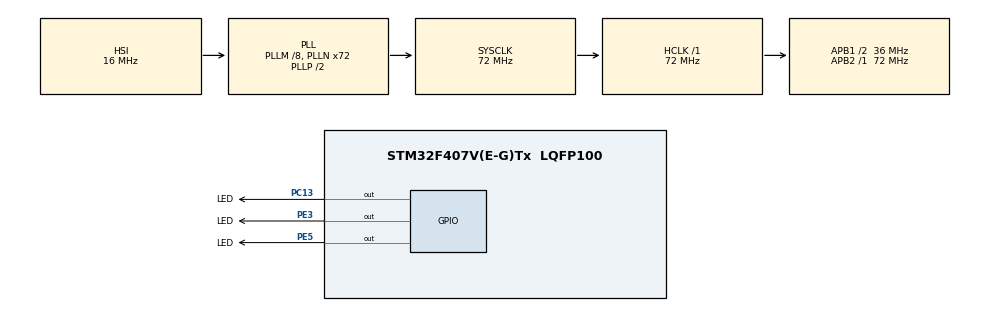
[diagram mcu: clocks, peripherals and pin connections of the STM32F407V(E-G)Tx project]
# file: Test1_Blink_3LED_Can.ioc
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Mcu.Family=STM32F4
PC15-OSC32_OUT.Mode=LSE-External-Oscillator
PH0-OSC_IN.Signal=RCC_OSC_IN
RCC.CortexFreq_Value=72000000
PC13-ANTI_TAMP.GPIO_Label=LED
RCC.APB1CLKDivider=RCC_HCLK_DIV2
PC14-OSC32_IN.Signal=RCC_OSC32_IN
PC13-ANTI_TAMP.PinState=GPIO_PIN_SET
RCC.SYSCLKSource=RCC_SYSCLKSOURCE_PLLCLK
ProjectManager.StackSize=0x400
PA0-WKUP.Signal=SYS_WKUP
PA0-WKUP.Mode=SYS_WakeUp0
PA13.Signal=SYS_JTMS-SWDIO
ProjectManager.TargetToolchain=STM32CubeIDE
RCC.HCLKFreq_Value=72000000
RCC.APB2TimFreq_Value=72000000
PE5.Signal=GPIO_Output
PC15-OSC32_OUT.Signal=RCC_OSC32_OUT
RCC.AHBFreq_Value=72000000
PH0-OSC_IN.Mode=HSE-External-Oscillator
PE3.PinState=GPIO_PIN_SET
RCC.HSE_VALUE=25000000
board=custom
PC13-ANTI_TAMP.Signal=GPIO_Output
RCC.VCOOutputFreq_Value=144000000
RCC.APB2Freq_Value=72000000
PC14-OSC32_IN.Mode=LSE-External-Oscillator
PA14.Mode=Serial_Wire
PE5.PinState=GPIO_PIN_SET
PH1-OSC_OUT.Signal=RCC_OSC_OUT
PA13.Mode=Serial_Wire
Mcu.Name=STM32F407V(E-G)Tx
PH1-OSC_OUT.Mode=HSE-External-Oscillator
RCC.48MHZClocksFreq_Value=36000000
RCC.SYSCLKFreq_VALUE=72000000
Mcu.Package=LQFP100
PE5.GPIO_Label=LED
PA14.Signal=SYS_JTCK-SWCLK
ProjectManager.HeapSize=0x200
RCC.HSI_VALUE=16000000
NVIC.PriorityGroup=NVIC_PRIORITYGROUP_4
RCC.PLLM=8
RCC.PLLN=72
RCC.APB1TimFreq_Value=72000000
PE3.Signal=GPIO_Output
PE3.GPIO_Label=LED
RCC.APB1Freq_Value=36000000

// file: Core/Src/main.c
/* USER CODE BEGIN Header */
/**
  ******************************************************************************
  * @file           : main.c
  * @brief          : Main program body
  ******************************************************************************
  * @attention
  *
  * <h2><center>&copy; Copyright (c) 2021 STMicroelectronics.
  * All rights reserved.</center></h2>
  *
  * This software component is licensed by ST under BSD 3-Clause license,
  * the "License"; You may not use this file except in compliance with the
  * License. You may obtain a copy of the License at:
  *                        opensource.org/licenses/BSD-3-Clause
  *
  ******************************************************************************
  */
/* USER CODE END Header */
#include "main.h"
#include "gpio.h"

void SystemClock_Config(void);

int main(void)
{

  /* MCU Configuration--------------------------------------------------------*/

  /* Reset of all peripherals, Initializes the Flash interface and the Systick. */
  HAL_Init();

  /* Configure the system clock */
  SystemClock_Config();

  /* Initialize all configured peripherals */
  MX_GPIO_Init();

  /* Infinite loop */
  while (1)
  {

    /* USER CODE BEGIN 3 */
	  HAL_GPIO_WritePin(GPIOE, GPIO_PIN_3, GPIO_PIN_SET);
	  HAL_GPIO_WritePin(GPIOE, GPIO_PIN_5, GPIO_PIN_RESET);
	  HAL_GPIO_WritePin(GPIOC, GPIO_PIN_13, GPIO_PIN_RESET);
	  HAL_Delay(50);
	  HAL_GPIO_WritePin(GPIOE, GPIO_PIN_5, GPIO_PIN_SET);
	  HAL_GPIO_WritePin(GPIOE, GPIO_PIN_3, GPIO_PIN_RESET);
	  HAL_GPIO_WritePin(GPIOC, GPIO_PIN_13, GPIO_PIN_RESET);
	  HAL_Delay(50);
	  HAL_GPIO_WritePin(GPIOC, GPIO_PIN_13, GPIO_PIN_SET);
	  HAL_GPIO_WritePin(GPIOE, GPIO_PIN_3, GPIO_PIN_RESET);
	  HAL_GPIO_WritePin(GPIOE, GPIO_PIN_5,GPIO_PIN_RESET);
	  HAL_Delay(50);
  }
  /* USER CODE END 3 */
}

void SystemClock_Config(void)
{
  RCC_OscInitTypeDef RCC_OscInitStruct = {0};
  RCC_ClkInitTypeDef RCC_ClkInitStruct = {0};

  /** Configure the main internal regulator output voltage
  */
  __HAL_RCC_PWR_CLK_ENABLE();
  __HAL_PWR_VOLTAGESCALING_CONFIG(PWR_REGULATOR_VOLTAGE_SCALE1);
  /** Initializes the RCC Oscillators according to the specified parameters
  * in the RCC_OscInitTypeDef structure.
  */
  RCC_OscInitStruct.OscillatorType = RCC_OSCILLATORTYPE_HSI;
  RCC_OscInitStruct.HSIState = RCC_HSI_ON;
  RCC_OscInitStruct.HSICalibrationValue = RCC_HSICALIBRATION_DEFAULT;
  RCC_OscInitStruct.PLL.PLLState = RCC_PLL_ON;
  RCC_OscInitStruct.PLL.PLLSource = RCC_PLLSOURCE_HSI;
  RCC_OscInitStruct.PLL.PLLM = 8;
  RCC_OscInitStruct.PLL.PLLN = 72;
  RCC_OscInitStruct.PLL.PLLP = RCC_PLLP_DIV2;
  RCC_OscInitStruct.PLL.PLLQ = 4;
  if (HAL_RCC_OscConfig(&RCC_OscInitStruct) != HAL_OK)
  {
    Error_Handler();
  }
  /** Initializes the CPU, AHB and APB buses clocks
  */
  RCC_ClkInitStruct.ClockType = RCC_CLOCKTYPE_HCLK|RCC_CLOCKTYPE_SYSCLK
                              |RCC_CLOCKTYPE_PCLK1|RCC_CLOCKTYPE_PCLK2;
  RCC_ClkInitStruct.SYSCLKSource = RCC_SYSCLKSOURCE_PLLCLK;
  RCC_ClkInitStruct.AHBCLKDivider = RCC_SYSCLK_DIV1;
  RCC_ClkInitStruct.APB1CLKDivider = RCC_HCLK_DIV2;
  RCC_ClkInitStruct.APB2CLKDivider = RCC_HCLK_DIV1;

  if (HAL_RCC_ClockConfig(&RCC_ClkInitStruct, FLASH_LATENCY_2) != HAL_OK)
  {
    Error_Handler();
  }
}

void Error_Handler(void)
{
  __disable_irq();
  while (1)
  {
  }
}

/************************ (C) COPYRIGHT STMicroelectronics *****END OF FILE****/
